# EFR32FG23B010F512IM48 register map
Vendor: Silicon Labs; Series: EFR32; File version: C
CPU: CM33 r0p4, little endian, MPU, FPU, DSP, VTOR, 4 interrupt priority bits, 8 SAU regions
Registers are 32-bit, read-write, reset 0x0 unless marked. A register's access mark holds for its fields unless they carry their own. Offsets are from the block's base; [hi:lo] are bit positions; {n}, {i} and the like mark numbered series; 'fields as' and 'values as' point back to an identical list.

## SCRATCHPAD_NS — SCRATCHPAD_NS Registers
Base 0x50000000
Same registers: SCRATCHPAD_S 0x40000000
0x00 SREG0 — Used for SIMCTRL Pointer in Verification Environment
  [31:0] SCRATCH — Scratch Pad Register
0x04 SREG1 — Used for SIMCTRL Data Access in Verification Environment
  [31:0] SCRATCH

## SEMAILBOX_NS_HOST — SEMAILBOX_NS_HOST Registers
Base 0x5C000000
Same registers: SEMAILBOX_S_HOST 0x4C000000
0x00 FIFO — A write access to any address in this area will be mapped to the TX FIFO (only for the payload). A read access to any address in this area will be mapped to the RX FIFO (only for the payload). Using an address range (16 x 32-bit) rather than one single address mapped to the FIFO allows using incremental bursts.
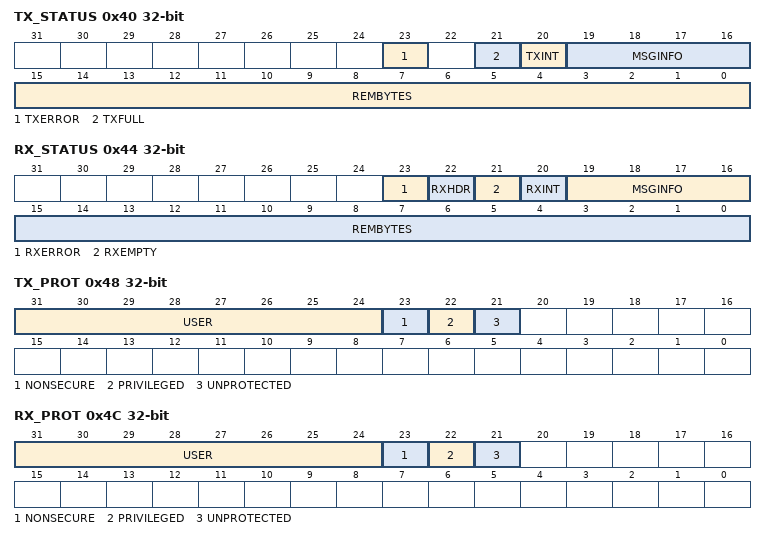
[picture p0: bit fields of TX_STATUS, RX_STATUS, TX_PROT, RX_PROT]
0x40 TX_STATUS ro
  [23] TXERROR, [21] TXFULL, [20] TXINT, [19:16] MSGINFO, [15:0] REMBYTES
0x44 RX_STATUS ro
  [23] RXERROR, [22] RXHDR, [21] RXEMPTY, [20] RXINT, [19:16] MSGINFO, [15:0] REMBYTES
0x48 TX_PROT ro — TX Protection register.
  [31:24] USER, [23] NONSECURE, [22] PRIVILEGED, [21] UNPROTECTED
0x4C RX_PROT ro — RX Protection register.
  [31:24] USER, [23] NONSECURE, [22] PRIVILEGED, [21] UNPROTECTED
0x50 TX_HEADER wo — A write access to this register will be mapped to the TX FIFO (only for header).
  [31:0] TXHEADER
0x54 RX_HEADER ro — A read access to this register will be mapped to the RX FIFO (only for the header).
  [31:0] RXHEADER
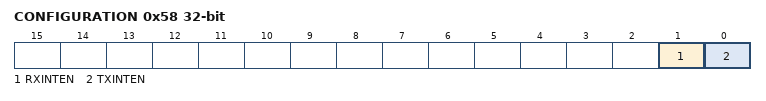
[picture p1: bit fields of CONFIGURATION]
0x58 CONFIGURATION
  [1] RXINTEN, [0] TXINTEN

## SMU_NS_CFGNS — SMU_NS_CFGNS Registers
Base 0x5400C000
Same registers: SMU_S_CFGNS 0x4400C000
0x04 NSSTATUS ro
  [0] SMUNSLOCK
    0=UNLOCKED; 1=LOCKED
0x08 NSLOCK wo
  [23:0] SMUNSLOCKKEY
    0xACCE55=UNLOCK (Unlocks Registers)
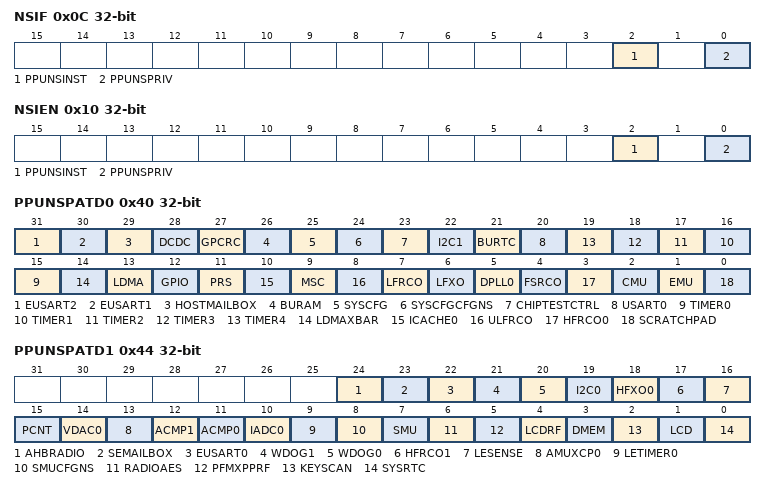
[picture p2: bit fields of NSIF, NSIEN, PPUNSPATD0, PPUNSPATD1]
0x0C NSIF
  [2] PPUNSINST — PPUNS Instruction Interrupt Flag
  [0] PPUNSPRIV — PPUNS Privilege Interrupt Flag
0x10 NSIEN
  [2] PPUNSINST — PPUNS Instruction Interrupt Enable
  [0] PPUNSPRIV — PPUNS Privilege Interrupt Enable
0x40 PPUNSPATD0 — Set peripheral bits to 1 to mark as privileged access only
  [31] EUSART2 — EUSART2 Privileged Access
  [30] EUSART1 — EUSART1 Privileged Access
  [29] HOSTMAILBOX — HOSTMAILBOX Privileged Access
  [28] DCDC — DCDC Privileged Access
  [27] GPCRC — GPCRC Privileged Access
  [26] BURAM — BURAM Privileged Access
  [25] SYSCFG — SYSCFG Privileged Access
  [24] SYSCFGCFGNS — SYSCFGCFGNS Privileged Access
  [23] CHIPTESTCTRL — CHIPTESTCTRL Privileged Access
  [22] I2C1 — I2C1 Privileged Access
  [21] BURTC — BURTC Privileged Access
  [20] USART0 — USART0 Privileged Access
  [n+15] TIMER{n} (n=0..4) — TIMER{n} Privileged Access
  [14] LDMAXBAR — LDMAXBAR Privileged Access
  [13] LDMA — LDMA Privileged Access
  [12] GPIO — GPIO Privileged Access
  [11] PRS — PRS Privileged Access
  [10] ICACHE0 — ICACHE0 Privileged Access
  [9] MSC — MSC Privileged Access
  [8] ULFRCO — ULFRCO Privileged Access
  [7] LFRCO — LFRCO Privileged Access
  [6] LFXO — LFXO Privileged Access
  [5] DPLL0 — DPLL0 Privileged Access
  [4] FSRCO — FSRCO Privileged Access
  [3] HFRCO0 — HFRCO0 Privileged Access
  [2] CMU — CMU Privileged Access
  [1] EMU — EMU Privileged Access
  [0] SCRATCHPAD — SCRATCHPAD Privileged Access
0x44 PPUNSPATD1 — Set peripheral bits to 1 to mark as privileged access only
  [24] AHBRADIO — AHBRADIO Privileged Access
  [23] SEMAILBOX — SEMAILBOX Privileged Access
  [22] EUSART0 — EUSART0 Privileged Access
  [21] WDOG1 — WDOG1 Privileged Access
  [20] WDOG0 — WDOG0 Privileged Access
  [19] I2C0 — I2C0 Privileged Access
  [18] HFXO0 — HFXO0 Privileged Access
  [17] HFRCO1 — HFRCO1 Privileged Access
  [16] LESENSE — LESENSE Privileged Access
  [15] PCNT — PCNT Privileged Access
  [14] VDAC0 — VDAC0 Privileged Access
  [13] AMUXCP0 — AMUXCP0 Privileged Access
  [12] ACMP1 — ACMP1 Privileged Access
  [11] ACMP0 — ACMP0 Privileged Access
  [10] IADC0 — IADC0 Privileged Access
  [9] LETIMER0 — LETIMER0 Privileged Access
  [8] SMUCFGNS — SMUCFGNS Privileged Access
  [7] SMU — SMU Privileged Access
  [6] RADIOAES — RADIOAES Privileged Access
  [5] PFMXPPRF — PFMXPPRF Privileged Access
  [4] LCDRF — LCDRF Privileged Access
  [3] DMEM — DMEM Privileged Access
  [2] KEYSCAN — KEYSCAN Privileged Access
  [1] LCD — LCD Privileged Access
  [0] SYSRTC — SYSRTC Privileged Access
0x140 PPUNSFS ro
  [7:0] PPUFSPERIPHID — Peripheral I
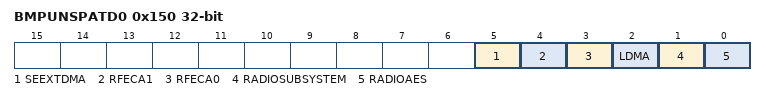
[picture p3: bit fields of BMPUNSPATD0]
0x150 BMPUNSPATD0
  [5] SEEXTDMA — SEEXTDMA privileged mode
  [4] RFECA1 — RFECA1 privileged mode
  [3] RFECA0 — RFECA0 privileged mode
  [2] LDMA — MCU LDMA privileged mode
  [1] RADIOSUBSYSTEM — RADIO subsystem manager privileged mode
  [0] RADIOAES — RADIO AES DMA privileged mode

## SYSCFG_NS_CFGNS — SYSCFG_NS_CFGNS Registers
Base 0x50078000
Same registers: SYSCFG_S_CFGNS 0x40078000
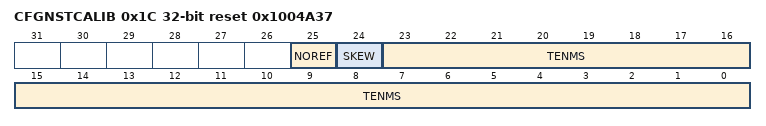
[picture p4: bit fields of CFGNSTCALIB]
0x1C CFGNSTCALIB reset 0x1004A37 — Configure to define the system tick for the M33.
  [25] NOREF — No Reference
    0=REF (Reference clock is implemented); 1=NOREF (Reference clock is not implemented)
  [24] SKEW
  [23:0] TENMS — Ten Milliseconds
0x600 ROOTNSDATA0 — Generic data space for user to pass to root, e.g., address of struct in mem
  [31:0] DATA
0x604 ROOTNSDATA1 — Generic data space for user to pass to root, e.g., address of struct in mem
  [31:0] DATA

## SYSRTC0_NS — SYSRTC0_NS Registers
Base 0x500A8000
Same registers: SYSRTC0_S 0x400A8000
0x00 IPVERSION ro reset 0x1
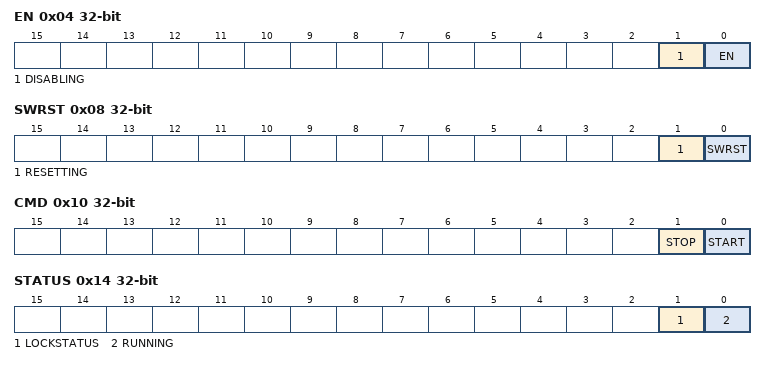
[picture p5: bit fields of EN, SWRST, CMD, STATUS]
0x04 EN
  [1] DISABLING ro — Disablement busy status
  [0] EN — SYSRTC Enable
0x08 SWRST
  [1] RESETTING ro — Software reset busy status
  [0] SWRST wo — Software reset command
0x0C CFG
  [0] DEBUGRUN — Debug Mode Run Enable
    0=DISABLE (SYSRTC is frozen in debug mode); 1=ENABLE (SYSRTC is running in debug mode)
0x10 CMD wo
  [1] STOP — Stop SYSRTC
  [0] START — Start SYSRTC
0x14 STATUS ro
  [1] LOCKSTATUS
    0=UNLOCKED (SYSRTC registers are unlocked); 1=LOCKED (SYSRTC registers are locked)
  [0] RUNNING — SYSRTC running status
0x18 CNT
  [31:0] CNT — Counter Value
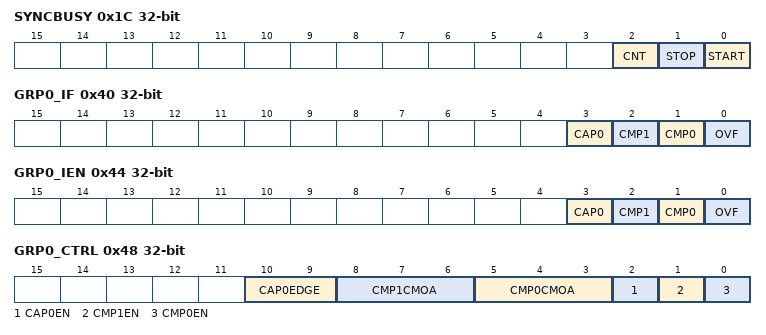
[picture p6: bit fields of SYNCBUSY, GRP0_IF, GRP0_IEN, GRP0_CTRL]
0x1C SYNCBUSY ro
  [2] CNT — Sync busy for CNT bitfield
  [1] STOP — Sync busy for STOP bitfield
  [0] START — Sync busy for START bitfield
0x20 LOCK wo
  [15:0] LOCKKEY — Configuration Lock Key
    0x4776=UNLOCK (Write to unlock SYSRTC lockable registers)
0x40 GRP0_IF
  [3] CAP0 — Capture 0 Interrupt Flag
  [2] CMP1 — Compare 1 Interrupt Flag
  [1] CMP0 — Compare 0 Interrupt Flag
  [0] OVF — Overflow Interrupt Flag
0x44 GRP0_IEN
  [3] CAP0 — Capture 0 Interrupt Enable
  [2] CMP1 — Compare 1 Interrupt Enable
  [1] CMP0 — Compare 0 Interrupt Enable
  [0] OVF — Overflow Interrupt Enable
0x48 GRP0_CTRL
  [10:9] CAP0EDGE — Capture 0 Edge Select
    0=RISING (Rising edges detected); 1=FALLING (Falling edges detected); 2=BOTH (Both edges detected)
  [8:6] CMP1CMOA — Compare 1 Compare Match Output Action
    0=CLEAR (Cleared on the next cycle); 1=SET (Set on the next cycle); 2=PULSE (Set on the next cycle, cleared on the cycle after); 3=TOGGLE (Inverted on the next cycle); 4=CMPIF (Export this channel's CMP IF)
  [5:3] CMP0CMOA — Compare 0 Compare Match Output Action
    values as CMP1CMOA
  [2] CAP0EN — Capture 0 Enable
  [1] CMP1EN — Compare 1 Enable
  [0] CMP0EN — Compare 0 Enable
0x4C GRP0_CMP0VALUE
  [31:0] CMP0VALUE — Compare 0 Value
0x50 GRP0_CMP1VALUE
  [31:0] CMP1VALUE — Compare 1 Value
0x54 GRP0_CAP0VALUE ro
  [31:0] CAP0VALUE — Capture 0 Value
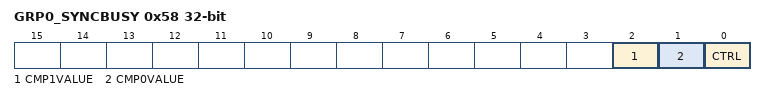
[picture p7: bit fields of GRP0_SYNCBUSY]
0x58 GRP0_SYNCBUSY ro
  [2] CMP1VALUE — Sync busy for CMP1VALUE register
  [1] CMP0VALUE — Sync busy for CMP0VALUE register
  [0] CTRL — Sync busy for CTRL register

## ULFRCO_NS — ULFRCO_NS Registers
Base 0x50028000
Same registers: ULFRCO_S 0x40028000
0x00 IPVERSION ro reset 0x1
  [31:0] IPVERSION — ULFRCO IP version
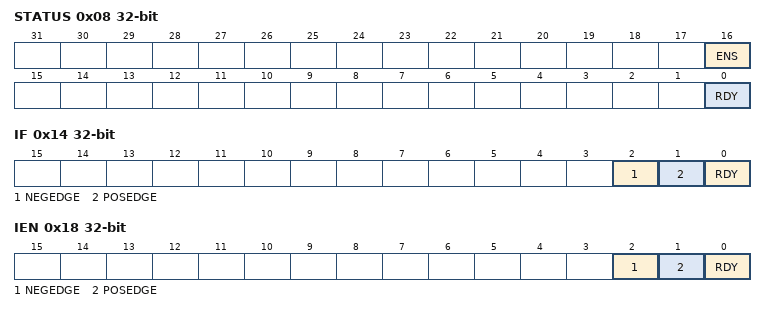
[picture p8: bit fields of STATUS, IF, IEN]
0x08 STATUS ro
  [16] ENS — Enable Status
  [0] RDY — Ready Status
0x14 IF
  [2] NEGEDGE — Negative Edge Interrupt Flag
  [1] POSEDGE — Positive Edge Interrupt Flag
  [0] RDY — Ready Interrupt Flag
0x18 IEN
  [2] NEGEDGE — Enable Negative Edge Interrupt
  [1] POSEDGE — Enable Positive Edge Interrupt
  [0] RDY — Enable Ready Interrupt
